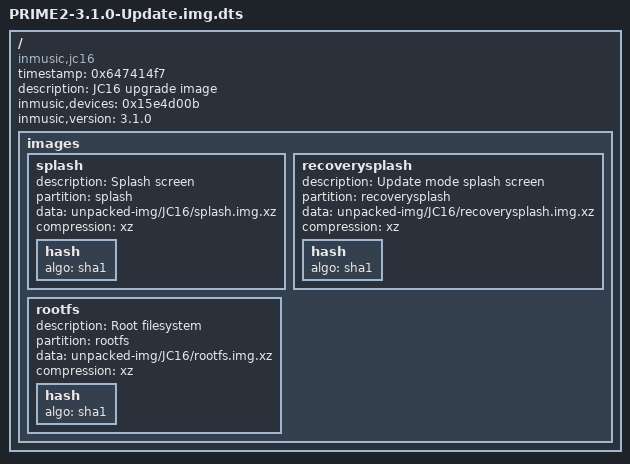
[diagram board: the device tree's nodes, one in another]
/dts-v1/;

/ {
	timestamp = <0x647414f7>;
	description = "JC16 upgrade image";
	compatible = "inmusic,jc16";
	inmusic,devices = <0x15e4d00b>;
	inmusic,version = "3.1.0";

	images {

		splash {
			description = "Splash screen";
			partition = "splash";
			data = /incbin/("unpacked-img/JC16/splash.img.xz");
			compression = "xz";

			hash {
				algo = "sha1";
			};
		};

		recoverysplash {
			description = "Update mode splash screen";
			partition = "recoverysplash";
			data = /incbin/("unpacked-img/JC16/recoverysplash.img.xz");
			compression = "xz";

			hash {
				algo = "sha1";
			};
		};

		rootfs {
			description = "Root filesystem";
			partition = "rootfs";
			data = /incbin/("unpacked-img/JC16/rootfs.img.xz");
			compression = "xz";

			hash {
				algo = "sha1";
			};
		};
	};
};
